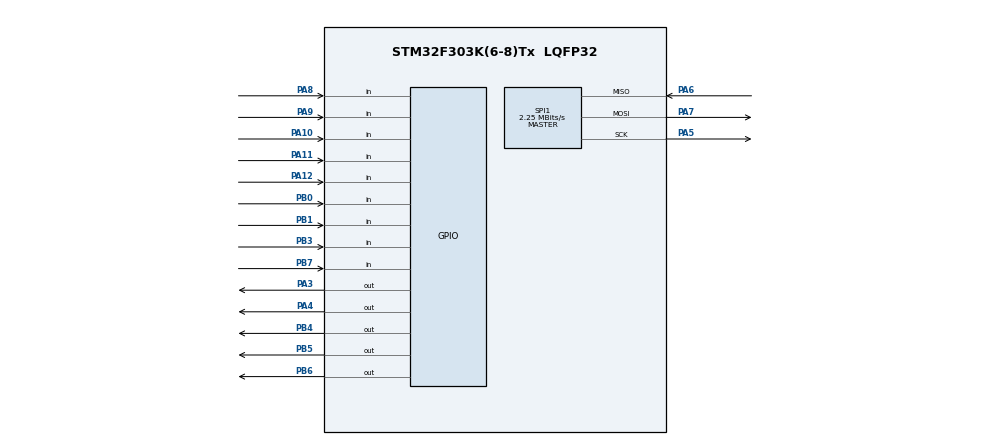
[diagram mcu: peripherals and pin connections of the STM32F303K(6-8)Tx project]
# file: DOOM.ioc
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Mcu.Family=STM32F3
Mcu.Name=STM32F303K(6-8)Tx
Mcu.Package=LQFP32
NVIC.PriorityGroup=NVIC_PRIORITYGROUP_4
PA10.Signal=GPIO_Input
PA11.Signal=GPIO_Input
PA12.Signal=GPIO_Input
PA13.Mode=Serial_Wire
PA13.Signal=SYS_JTMS-SWDIO
PA14.Mode=Serial_Wire
PA14.Signal=SYS_JTCK-SWCLK
PA3.Signal=GPIO_Output
PA4.Signal=GPIO_Output
PA5.Mode=Full_Duplex_Master
PA5.Signal=SPI1_SCK
PA6.Mode=Full_Duplex_Master
PA6.Signal=SPI1_MISO
PA7.Mode=Full_Duplex_Master
PA7.Signal=SPI1_MOSI
PA8.Signal=GPIO_Input
PA9.Signal=GPIO_Input
PB0.Signal=GPIO_Input
PB1.Signal=GPIO_Input
PB3.Signal=GPIO_Input
PB4.GPIO_Speed=GPIO_SPEED_FREQ_LOW
PB4.Signal=GPIO_Output
PB5.GPIO_Speed=GPIO_SPEED_FREQ_LOW
PB5.Signal=GPIO_Output
PB6.GPIO_FM6=SYSCFG_CFGR1_I2C_PB6_FMP
PB6.GPIO_Speed=GPIO_SPEED_FREQ_LOW
PB6.Signal=GPIO_Output
PB7.Signal=GPIO_Input
PF0\ /\ OSC_IN.Mode=HSE-External-Oscillator
PF0\ /\ OSC_IN.Signal=RCC_OSC_IN
PF1\ /\ OSC_OUT.Mode=HSE-External-Oscillator
PF1\ /\ OSC_OUT.Signal=RCC_OSC_OUT
ProjectManager.HeapSize=0x200
ProjectManager.StackSize=0x400
ProjectManager.TargetToolchain=STM32CubeIDE
RCC.AHBFreq_Value=72000000
RCC.APB1CLKDivider=RCC_HCLK_DIV2
RCC.APB1Freq_Value=36000000
RCC.APB1TimFreq_Value=72000000
RCC.APB2Freq_Value=72000000
RCC.APB2TimFreq_Value=72000000
RCC.CortexFreq_Value=72000000
RCC.HCLKFreq_Value=72000000
RCC.HSE_VALUE=8000000
RCC.HSI_VALUE=8000000
RCC.PLLMUL=RCC_PLL_MUL9
RCC.PLLSourceVirtual=RCC_PLLSOURCE_HSE
RCC.SYSCLKFreq_VALUE=72000000
RCC.SYSCLKSourceVirtual=RCC_SYSCLKSOURCE_PLLCLK
SPI1.BaudRatePrescaler=SPI_BAUDRATEPRESCALER_32
SPI1.CalculateBaudRate=2.25 MBits/s
SPI1.DataSize=SPI_DATASIZE_8BIT
SPI1.Direction=SPI_DIRECTION_2LINES
SPI1.Mode=SPI_MODE_MASTER
SPI1.VirtualType=VM_MASTER
board=custom

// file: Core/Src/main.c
/* USER CODE BEGIN Header */
/**
  ******************************************************************************
  * @file           : main.c
  * @brief          : Main program body
  ******************************************************************************
  * @attention
  *
  * <h2><center>&copy; Copyright (c) 2019 STMicroelectronics.
  * All rights reserved.</center></h2>
  *
  * This software component is licensed by ST under BSD 3-Clause license,
  * the "License"; You may not use this file except in compliance with the
  * License. You may obtain a copy of the License at:
  *                        opensource.org/licenses/BSD-3-Clause
  *
  ******************************************************************************
  */
/* USER CODE END Header */
#include "main.h"
#include "spi.h"
#include "gpio.h"
#include "ili9163.h"
#include "menu.h"
#include <stdio.h>
#include <string.h>
#include <gameLogic.h>

void SystemClock_Config(void);
void MX_GPIO_Init(void);
void MX_SPI1_Init(void);

/* USER CODE BEGIN 0 */
uint8_t rx_data = 0;
/* USER CODE END 0 */

int main(void)
{

  /* MCU Configuration--------------------------------------------------------*/

  /* Reset of all peripherals, Initializes the Flash interface and the Systick. */
	LL_APB2_GRP1_EnableClock(LL_APB2_GRP1_PERIPH_SYSCFG);
	LL_APB1_GRP1_EnableClock(LL_APB1_GRP1_PERIPH_PWR);

	NVIC_SetPriorityGrouping(NVIC_PRIORITYGROUP_4);

  /* Configure the system clock */
  SystemClock_Config();

  /* Initialize all configured peripherals */
  MX_GPIO_Init();
  MX_SPI1_Init();

  initCD_Pin();
  initCS_Pin();
  initRES_Pin();

  LL_mDelay(1);

  uint8_t buttonD4_val = 1;		//NOT NEEDED NOW

  /* USER CODE BEGIN 2 */
  lcdInitialise(LCD_ORIENTATION3);
  lcdClearDisplay(decodeRgbValue(0, 0, 0));

  /* USER CODE END 2 */

  /* Infinite loop */
  while (1)
  {

    /* USER CODE BEGIN 3 */
	//buttonD4_val = LL_GPIO_ReadInputPort(LL_GPIO_PIN_ALL);

	buttonD4_val = LL_GPIO_IsInputPinSet(GPIOB,GPIO_PIN_4);
	if(buttonD4_val == 0)
	{
	  menu();
	  LL_mDelay(300);
	}
  }
  /* USER CODE END 3 */
}

void SystemClock_Config(void)
{
	LL_FLASH_SetLatency(LL_FLASH_LATENCY_0);

	  if(LL_FLASH_GetLatency() != LL_FLASH_LATENCY_0)
	  {
	  Error_Handler();
	  }
	  LL_RCC_HSI_Enable();

	   // Wait till HSI is ready
	  while(LL_RCC_HSI_IsReady() != 1)
	  {

	  }
	  LL_RCC_HSI_SetCalibTrimming(16);
	  LL_RCC_SetAHBPrescaler(LL_RCC_SYSCLK_DIV_1);
	  LL_RCC_SetAPB1Prescaler(LL_RCC_APB1_DIV_1);
	  LL_RCC_SetAPB2Prescaler(LL_RCC_APB1_DIV_1);
	  LL_RCC_SetSysClkSource(LL_RCC_SYS_CLKSOURCE_HSI);

	   // Wait till System clock is ready
	  while(LL_RCC_GetSysClkSource() != LL_RCC_SYS_CLKSOURCE_STATUS_HSI)
	  {

	  }
	  LL_Init1msTick(8000000);
	  LL_SYSTICK_SetClkSource(LL_SYSTICK_CLKSOURCE_HCLK);
	  LL_SetSystemCoreClock(8000000);
}

void Error_Handler(void)
{
}
